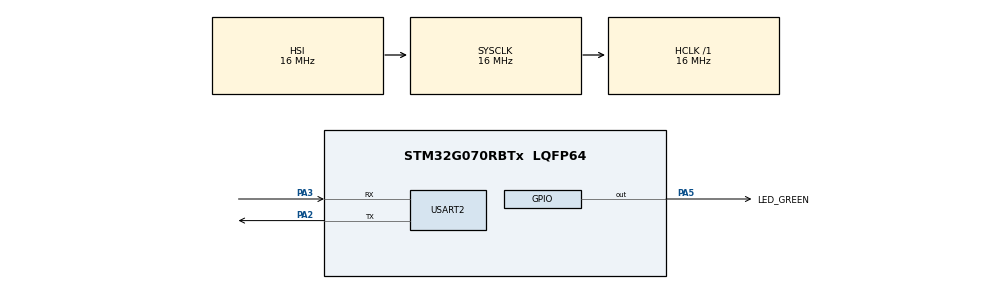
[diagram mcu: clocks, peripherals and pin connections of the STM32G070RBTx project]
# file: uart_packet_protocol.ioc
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CRC.CRCLength=CRC_POLYLENGTH_8B
CRC.DefaultPolynomialUse=DEFAULT_POLYNOMIAL_DISABLE
Dma.DMA_GENERATOR0.2.Direction=DMA_PERIPH_TO_MEMORY
Dma.DMA_GENERATOR0.2.EventEnable=DISABLE
Dma.DMA_GENERATOR0.2.Instance=DMA1_Channel3
Dma.DMA_GENERATOR0.2.MemDataAlignment=DMA_MDATAALIGN_BYTE
Dma.DMA_GENERATOR0.2.MemInc=DMA_MINC_ENABLE
Dma.DMA_GENERATOR0.2.Mode=DMA_NORMAL
Dma.DMA_GENERATOR0.2.PeriphDataAlignment=DMA_PDATAALIGN_BYTE
Dma.DMA_GENERATOR0.2.PeriphInc=DMA_PINC_DISABLE
Dma.DMA_GENERATOR0.2.Polarity=HAL_DMAMUX_REQ_GEN_RISING
Dma.DMA_GENERATOR0.2.Priority=DMA_PRIORITY_LOW
Dma.DMA_GENERATOR0.2.RequestNumber=1
Dma.DMA_GENERATOR0.2.SignalID=NONE
Dma.DMA_GENERATOR0.2.SyncEnable=DISABLE
Dma.DMA_GENERATOR0.2.SyncPolarity=HAL_DMAMUX_SYNC_NO_EVENT
Dma.DMA_GENERATOR0.2.SyncRequestNumber=1
Dma.DMA_GENERATOR0.2.SyncSignalID=NONE
Dma.Request0=USART2_RX
Dma.Request1=USART2_TX
Dma.Request2=DMA_GENERATOR0
Dma.USART2_RX.0.Direction=DMA_PERIPH_TO_MEMORY
Dma.USART2_RX.0.EventEnable=DISABLE
Dma.USART2_RX.0.Instance=DMA1_Channel1
Dma.USART2_RX.0.MemDataAlignment=DMA_MDATAALIGN_BYTE
Dma.USART2_RX.0.MemInc=DMA_MINC_ENABLE
Dma.USART2_RX.0.Mode=DMA_NORMAL
Dma.USART2_RX.0.PeriphDataAlignment=DMA_PDATAALIGN_BYTE
Dma.USART2_RX.0.PeriphInc=DMA_PINC_DISABLE
Dma.USART2_RX.0.Polarity=HAL_DMAMUX_REQ_GEN_RISING
Dma.USART2_RX.0.Priority=DMA_PRIORITY_HIGH
Dma.USART2_RX.0.RequestNumber=1
Dma.USART2_RX.0.SignalID=NONE
Dma.USART2_RX.0.SyncEnable=DISABLE
Dma.USART2_RX.0.SyncPolarity=HAL_DMAMUX_SYNC_NO_EVENT
Dma.USART2_RX.0.SyncRequestNumber=1
Dma.USART2_RX.0.SyncSignalID=NONE
Dma.USART2_TX.1.Direction=DMA_MEMORY_TO_PERIPH
Dma.USART2_TX.1.EventEnable=DISABLE
Dma.USART2_TX.1.Instance=DMA1_Channel2
Dma.USART2_TX.1.MemDataAlignment=DMA_MDATAALIGN_BYTE
Dma.USART2_TX.1.MemInc=DMA_MINC_ENABLE
Dma.USART2_TX.1.Mode=DMA_NORMAL
Dma.USART2_TX.1.PeriphDataAlignment=DMA_PDATAALIGN_BYTE
Dma.USART2_TX.1.PeriphInc=DMA_PINC_DISABLE
Dma.USART2_TX.1.Polarity=HAL_DMAMUX_REQ_GEN_RISING
Dma.USART2_TX.1.Priority=DMA_PRIORITY_HIGH
Dma.USART2_TX.1.RequestNumber=1
Dma.USART2_TX.1.SignalID=NONE
Dma.USART2_TX.1.SyncEnable=DISABLE
Dma.USART2_TX.1.SyncPolarity=HAL_DMAMUX_SYNC_NO_EVENT
Dma.USART2_TX.1.SyncRequestNumber=1
Dma.USART2_TX.1.SyncSignalID=NONE
Mcu.Family=STM32G0
Mcu.Name=STM32G070RBTx
Mcu.Package=LQFP64
NVIC.DMA1_Ch4_7_DMAMUX1_OVR_IRQn=true\:0\:0\:false\:true\:true\:2\:false\:true\:true
NVIC.DMA1_Channel1_IRQn=true\:0\:0\:false\:true\:true\:4\:false\:true\:true
NVIC.DMA1_Channel2_3_IRQn=true\:0\:0\:false\:true\:true\:3\:false\:true\:true
NVIC.USART2_IRQn=true\:0\:0\:false\:true\:true\:1\:true\:true\:true
PA13.GPIO_Label=TMS
PA13.Signal=SYS_SWDIO
PA14-BOOT0.GPIO_Label=TCK
PA14-BOOT0.Signal=SYS_SWCLK
PA2.Mode=Asynchronous
PA2.Signal=USART2_TX
PA3.Mode=Asynchronous
PA3.Signal=USART2_RX
PA5.GPIO_Label=LED_GREEN
PA5.GPIO_Speed=GPIO_SPEED_FREQ_HIGH
PA5.Signal=GPIO_Output
PC13.Signal=SYS_WKUP2
PC14-OSC32_IN\ (PC14).Signal=RCC_OSC32_IN
PC15-OSC32_OUT\ (PC15).Signal=RCC_OSC32_OUT
PF0-OSC_IN\ (PF0).GPIO_Label=MCO
PF0-OSC_IN\ (PF0).Signal=RCC_OSC_IN
ProjectManager.HeapSize=0x200
ProjectManager.StackSize=0x400
ProjectManager.TargetToolchain=Makefile
RCC.AHBFreq_Value=16000000
RCC.CortexFreq_Value=16000000
RCC.EXTERNAL_CLOCK_VALUE=12288000
RCC.HCLKFreq_Value=16000000
RCC.HSE_VALUE=8000000
RCC.HSI_VALUE=16000000
RCC.LSE_VALUE=32768
RCC.SYSCLKFreq_VALUE=16000000
RCC.VCOOutputFreq_Value=128000000
USART2.FIFOMode=FIFOMODE_ENABLE
USART2.RXFIFOThreshold=RXFIFO_THRESHOLD_FULL
USART2.TXFIFOThreshold=TXFIFO_THRESHOLD_EMPTY
USART2.VirtualMode-Asynchronous=VM_ASYNC
VP_CRC_VS_CRC.Mode=CRC_Activate
board=NUCLEO-G070RB

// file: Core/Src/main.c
/* USER CODE BEGIN Header */
/**
 ******************************************************************************
 * @file           : main.c
 * @brief          : Main program body
 ******************************************************************************
 * @attention
 *
 * Copyright (c) 2026 STMicroelectronics.
 * All rights reserved.
 *
 * This software is licensed under terms that can be found in the LICENSE file
 * in the root directory of this software component.
 * If no LICENSE file comes with this software, it is provided AS-IS.
 *
 ******************************************************************************
 */
/* USER CODE END Header */
#include "main.h"
#include "crc.h"
#include "dma.h"
#include "usart.h"
#include "gpio.h"

/* USER CODE BEGIN Includes */
#include "zetta_protocol.h"
#include <string.h>
/* USER CODE END Includes */

/* USER CODE BEGIN PV */
uint8_t rx_byte = 0;
void uart_stm32_send_dma(void* data, uint8_t size);
void uart_stm32_receive_dma(void* data, uint8_t size);
uint32_t stm32_crc(uint32_t* data, uint32_t size);

void uart_stm32_send_dma(void* data, uint8_t size)
{
    HAL_UART_Transmit_DMA(&huart2, data, size);
}
void uart_stm32_receive_dma(void* data, uint8_t size)
{
    HAL_UART_Receive_DMA(&huart2, data, size);
}
uint32_t stm32_crc(uint32_t* data, uint32_t size)
{
    __HAL_CRC_DR_RESET(&hcrc);
    return HAL_CRC_Calculate(&hcrc, (uint32_t*)data, size);
}

// user data
#pragma pack(push, 1)
struct MetricPacket
{
    uint32_t a;
    float b;
    uint8_t str[5];
};
#pragma pack(pop)
struct MetricPacket metbj = {0};
Zetta_t hzettatx;
Zetta_t hzettarx;
ZettaInterface_t zetta1_interface = {
    .computeCRC = stm32_crc,
    .send = uart_stm32_send_dma,
    .receive = uart_stm32_receive_dma,
};
/* USER CODE END PV */

void SystemClock_Config(void);
static void MX_NVIC_Init(void);

/* USER CODE BEGIN 0 */
void HAL_UART_TxCpltCallback(UART_HandleTypeDef* huart)
{
    HAL_GPIO_WritePin(LED_GREEN_GPIO_Port, LED_GREEN_Pin, 1);
    zetta_transmit_cplt_clb(&hzettatx);
}
void HAL_UART_RxCpltCallback(UART_HandleTypeDef* huart)
{
    zetta_ParseByte(&hzettarx, rx_byte);
    zetta_recieve_cplt_clb(&hzettarx);
    HAL_UART_Receive_DMA(&huart2, &rx_byte, 1);
}
/* USER CODE END 0 */

int main(void)
{

  /* MCU Configuration--------------------------------------------------------*/

  /* Reset of all peripherals, Initializes the Flash interface and the Systick. */
  HAL_Init();

  /* Configure the system clock */
  SystemClock_Config();

  /* Initialize all configured peripherals */
  MX_GPIO_Init();
  MX_DMA_Init();
  MX_USART2_UART_Init();
  MX_CRC_Init();

  /* Initialize interrupts */
  MX_NVIC_Init();

  /* Infinite loop */
  /* USER CODE BEGIN WHILE */
    char test1[] = "hello world";
#pragma pack(push, 1)

    struct MyStruct
    {
        uint8_t test3[4];
        int age;
        float price;
    };
#pragma pack(pop)
    struct MyStruct test2;
    test2.age = 40;
    memcpy(test2.test3, "moka", 4);

    test2.price = 20.2f;
    // send_data((void*)&test2, sizeof(test2));g
    zetta_init(&hzettatx, zetta1_interface);
    zetta_send(&hzettatx, MSG_PUBLISH, &test2, sizeof(test2));
    zetta_send(&hzettatx, MSG_PUBLISH, test1, sizeof(test1));
    // send_data(test1, sizeof(test1));
    // buff_tx_size = protocol_pack(MSG_PUBLISH, test1, sizeof(test1), buff_tx);
    // buff_tx_size = protocol_pack(MSG_PUBLISH, &test2, sizeof(test2),
    // buff_tx);
    zetta_init(&hzettarx, zetta1_interface);

    HAL_UART_Receive_DMA(&huart2, &rx_byte, 1);
    // HAL_UART_Transmit_DMA(&huart2, buff_tx, buff_tx_size);
    while (1)
    {
        // HAL_GPIO_WritePin(LED_GREEN_GPIO_Port, LED_GREEN_Pin, 1);
        Zetta_GetPayload(&hzettarx, &metbj);
        HAL_Delay(1000);
    /* USER CODE END WHILE */

    }
}

void SystemClock_Config(void)
{
  RCC_OscInitTypeDef RCC_OscInitStruct = {0};
  RCC_ClkInitTypeDef RCC_ClkInitStruct = {0};

  /** Configure the main internal regulator output voltage
  */
  HAL_PWREx_ControlVoltageScaling(PWR_REGULATOR_VOLTAGE_SCALE1);

  /** Initializes the RCC Oscillators according to the specified parameters
  * in the RCC_OscInitTypeDef structure.
  */
  RCC_OscInitStruct.OscillatorType = RCC_OSCILLATORTYPE_HSI;
  RCC_OscInitStruct.HSIState = RCC_HSI_ON;
  RCC_OscInitStruct.HSIDiv = RCC_HSI_DIV1;
  RCC_OscInitStruct.HSICalibrationValue = RCC_HSICALIBRATION_DEFAULT;
  RCC_OscInitStruct.PLL.PLLState = RCC_PLL_NONE;
  if (HAL_RCC_OscConfig(&RCC_OscInitStruct) != HAL_OK)
  {
    Error_Handler();
  }

  /** Initializes the CPU, AHB and APB buses clocks
  */
  RCC_ClkInitStruct.ClockType = RCC_CLOCKTYPE_HCLK|RCC_CLOCKTYPE_SYSCLK
                              |RCC_CLOCKTYPE_PCLK1;
  RCC_ClkInitStruct.SYSCLKSource = RCC_SYSCLKSOURCE_HSI;
  RCC_ClkInitStruct.AHBCLKDivider = RCC_SYSCLK_DIV1;
  RCC_ClkInitStruct.APB1CLKDivider = RCC_HCLK_DIV1;

  if (HAL_RCC_ClockConfig(&RCC_ClkInitStruct, FLASH_LATENCY_0) != HAL_OK)
  {
    Error_Handler();
  }
}

/**
  * @brief NVIC Configuration.
  * @retval None
  */
static void MX_NVIC_Init(void)
{
  /* USART2_IRQn interrupt configuration */
  HAL_NVIC_SetPriority(USART2_IRQn, 0, 0);
  HAL_NVIC_EnableIRQ(USART2_IRQn);
  /* DMA1_Ch4_7_DMAMUX1_OVR_IRQn interrupt configuration */
  HAL_NVIC_SetPriority(DMA1_Ch4_7_DMAMUX1_OVR_IRQn, 0, 0);
  HAL_NVIC_EnableIRQ(DMA1_Ch4_7_DMAMUX1_OVR_IRQn);
  /* DMA1_Channel2_3_IRQn interrupt configuration */
  HAL_NVIC_SetPriority(DMA1_Channel2_3_IRQn, 0, 0);
  HAL_NVIC_EnableIRQ(DMA1_Channel2_3_IRQn);
  /* DMA1_Channel1_IRQn interrupt configuration */
  HAL_NVIC_SetPriority(DMA1_Channel1_IRQn, 0, 0);
  HAL_NVIC_EnableIRQ(DMA1_Channel1_IRQn);
}

void Error_Handler(void)
{
  /* USER CODE BEGIN Error_Handler_Debug */
    /* User can add his own implementation to report the HAL error return state
     */
    __disable_irq();
    while (1)
    {
    }
  /* USER CODE END Error_Handler_Debug */
}

#ifdef  USE_FULL_ASSERT
/**
  * @brief  Reports the name of the source file and the source line number
  *         where the assert_param error has occurred.
  * @param  file: pointer to the source file name
  * @param  line: assert_param error line source number
  * @retval None
  */
void assert_failed(uint8_t *file, uint32_t line)
{
  /* USER CODE BEGIN 6 */
    /* User can add his own implementation to report the file name and line
       number, ex: printf("Wrong parameters value: file %s on line %d\r\n",
       file, line) */
  /* USER CODE END 6 */
}
#endif /* USE_FULL_ASSERT */
